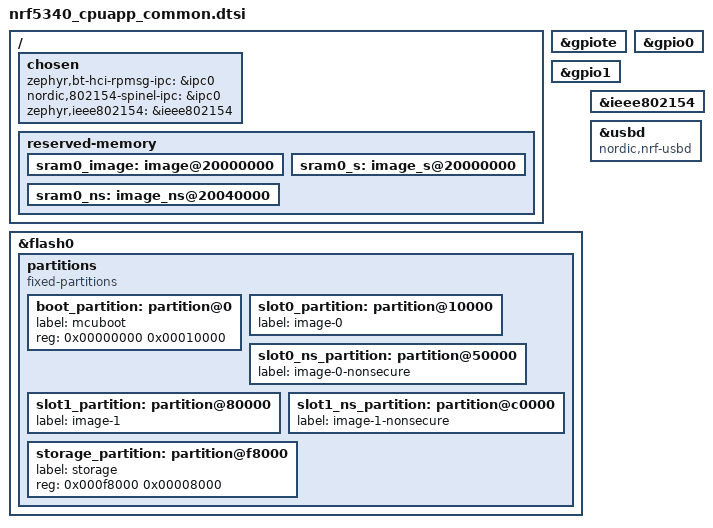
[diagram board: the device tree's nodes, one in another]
/*
 * Copyright (c) 2019-2020 Nordic Semiconductor ASA
 *
 * SPDX-License-Identifier: Apache-2.0
 */
 #include <zephyr/dt-bindings/input/input-event-codes.h>
 
 / {
 
     chosen {
         zephyr,bt-hci-rpmsg-ipc = &ipc0;
         nordic,802154-spinel-ipc = &ipc0;
         zephyr,ieee802154 = &ieee802154;
     }; 
 };
 
 &gpiote {
     status = "okay";
 };
 
 &gpio0 {
     
     status = "okay";
 };
 
 &gpio1 {
     status = "okay";
 };

 &flash0 {
 
     partitions {
         compatible = "fixed-partitions";
         #address-cells = <1>;
         #size-cells = <1>;
 
         boot_partition: partition@0 {
             label = "mcuboot";
             reg = <0x00000000 0x00010000>;
         };
         slot0_partition: partition@10000 {
             label = "image-0";
         };
         slot0_ns_partition: partition@50000 {
             label = "image-0-nonsecure";
         };
         slot1_partition: partition@80000 {
             label = "image-1";
         };
         slot1_ns_partition: partition@c0000 {
             label = "image-1-nonsecure";
         };
         /* 0xf0000 to 0xf7fff reserved for TF-M partitions */
         storage_partition: partition@f8000 {
             label = "storage";
             reg = <0x000f8000 0x00008000>;
         };
     };
 };
 
 &ieee802154 {
     status = "okay";
 };
 
 zephyr_udc0: &usbd {
     compatible = "nordic,nrf-usbd";
     status = "okay";
 };
 
 / {
 
     reserved-memory {
         #address-cells = <1>;
         #size-cells = <1>;
         ranges;
 
         sram0_image: image@20000000 {
             /* Zephyr image(s) memory */
         };
 
         sram0_s: image_s@20000000 {
             /* Secure image memory */
         };
 
         sram0_ns: image_ns@20040000 {
             /* Non-Secure image memory */
         };
     };
 };
 
 /* Include partition configuration file */
 #include "nrf5340_cpuapp_partition_conf.dtsi"
 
